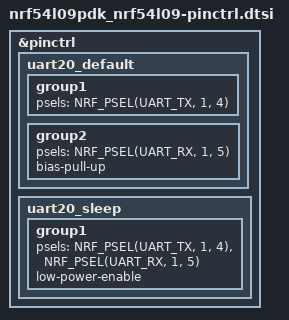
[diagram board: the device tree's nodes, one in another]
/*
 * Copyright (c) 2024 Nordic Semiconductor
 * SPDX-License-Identifier: Apache-2.0
 */

&pinctrl {
	/omit-if-no-ref/ uart20_default: uart20_default {
		group1 {
			psels = <NRF_PSEL(UART_TX, 1, 4)>;
		};
		group2 {
			psels = <NRF_PSEL(UART_RX, 1, 5)>;
			bias-pull-up;
		};
	};

	/omit-if-no-ref/ uart20_sleep: uart20_sleep {
		group1 {
			psels = <NRF_PSEL(UART_TX, 1, 4)>,
				<NRF_PSEL(UART_RX, 1, 5)>;
			low-power-enable;
		};
	};
};
